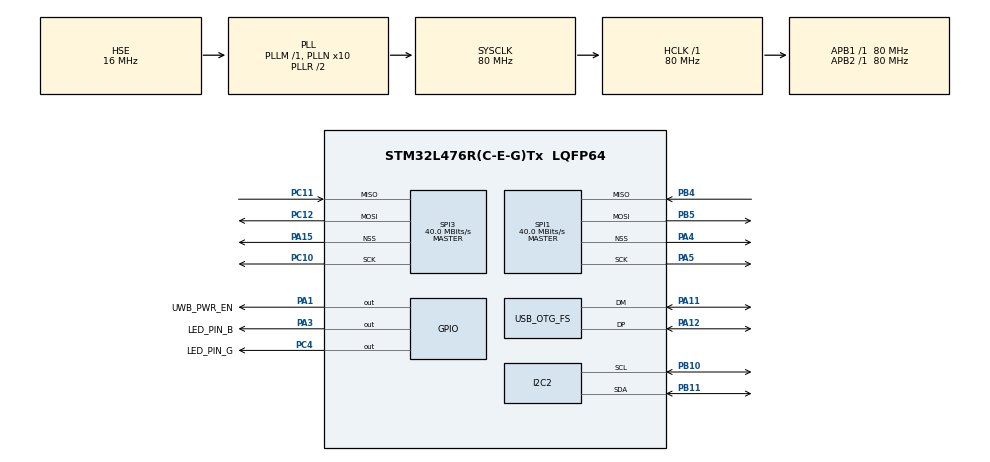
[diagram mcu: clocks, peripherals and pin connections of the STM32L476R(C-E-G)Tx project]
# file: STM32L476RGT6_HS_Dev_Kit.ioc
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I2C2.Timing=0x10D19CE4
Mcu.Family=STM32L4
Mcu.Name=STM32L476R(C-E-G)Tx
Mcu.Package=LQFP64
NVIC.OTG_FS_IRQn=true\:0\:0\:false\:false\:true\:false\:true\:true
NVIC.PriorityGroup=NVIC_PRIORITYGROUP_4
PA1.GPIO_Label=UWB_PWR_EN
PA1.Signal=GPIO_Output
PA11.Mode=Device_Only
PA11.Signal=USB_OTG_FS_DM
PA12.Mode=Device_Only
PA12.Signal=USB_OTG_FS_DP
PA13\ (JTMS-SWDIO).Mode=Trace_Asynchronous_SW
PA13\ (JTMS-SWDIO).Signal=SYS_JTMS-SWDIO
PA14\ (JTCK-SWCLK).Mode=Trace_Asynchronous_SW
PA14\ (JTCK-SWCLK).Signal=SYS_JTCK-SWCLK
PA15\ (JTDI).Mode=NSS_Signal_Hard_Output
PA15\ (JTDI).Signal=SPI3_NSS
PA3.GPIO_Label=LED_PIN_B
PA3.Signal=GPIO_Output
PA4.Mode=NSS_Signal_Hard_Output
PA4.Signal=SPI1_NSS
PA5.Mode=Full_Duplex_Master
PA5.Signal=SPI1_SCK
PB10.Mode=I2C
PB10.Signal=I2C2_SCL
PB11.Mode=I2C
PB11.Signal=I2C2_SDA
PB3\ (JTDO-TRACESWO).Mode=Trace_Asynchronous_SW
PB3\ (JTDO-TRACESWO).Signal=SYS_JTDO-SWO
PB4\ (NJTRST).Mode=Full_Duplex_Master
PB4\ (NJTRST).Signal=SPI1_MISO
PB5.Mode=Full_Duplex_Master
PB5.Signal=SPI1_MOSI
PC10.Mode=Full_Duplex_Master
PC10.Signal=SPI3_SCK
PC11.Mode=Full_Duplex_Master
PC11.Signal=SPI3_MISO
PC12.Mode=Full_Duplex_Master
PC12.Signal=SPI3_MOSI
PC14-OSC32_IN\ (PC14).Mode=LSE-External-Oscillator
PC14-OSC32_IN\ (PC14).Signal=RCC_OSC32_IN
PC15-OSC32_OUT\ (PC15).Mode=LSE-External-Oscillator
PC15-OSC32_OUT\ (PC15).Signal=RCC_OSC32_OUT
PC4.GPIO_Label=LED_PIN_G
PC4.Signal=GPIO_Output
PH0-OSC_IN\ (PH0).Mode=HSE-External-Oscillator
PH0-OSC_IN\ (PH0).Signal=RCC_OSC_IN
PH1-OSC_OUT\ (PH1).Mode=HSE-External-Oscillator
PH1-OSC_OUT\ (PH1).Signal=RCC_OSC_OUT
ProjectManager.HeapSize=0x200
ProjectManager.StackSize=0x400
ProjectManager.TargetToolchain=STM32CubeIDE
RCC.ADCFreq_Value=96000000
RCC.AHBFreq_Value=80000000
RCC.APB1Freq_Value=80000000
RCC.APB1TimFreq_Value=80000000
RCC.APB2Freq_Value=80000000
RCC.APB2TimFreq_Value=80000000
RCC.CortexFreq_Value=80000000
RCC.HCLKFreq_Value=80000000
RCC.HSE_VALUE=16000000
RCC.HSI_VALUE=16000000
RCC.MSI_VALUE=4000000
RCC.PLLN=10
RCC.PLLSAI1N=12
RCC.PLLSAI1Q=RCC_PLLQ_DIV4
RCC.PLLSourceVirtual=RCC_PLLSOURCE_HSE
RCC.RTCClockSelection=RCC_RTCCLKSOURCE_LSE
RCC.SYSCLKFreq_VALUE=80000000
RCC.SYSCLKSource=RCC_SYSCLKSOURCE_PLLCLK
RCC.USBFreq_Value=48000000
RCC.VCOOutputFreq_Value=160000000
SPI1.BaudRatePrescaler=SPI_BAUDRATEPRESCALER_2
SPI1.CalculateBaudRate=40.0 MBits/s
SPI1.Direction=SPI_DIRECTION_2LINES
SPI1.Mode=SPI_MODE_MASTER
SPI1.VirtualNSS=VM_NSSHARD
SPI1.VirtualType=VM_MASTER
SPI3.BaudRatePrescaler=SPI_BAUDRATEPRESCALER_2
SPI3.CalculateBaudRate=40.0 MBits/s
SPI3.Direction=SPI_DIRECTION_2LINES
SPI3.Mode=SPI_MODE_MASTER
SPI3.VirtualNSS=VM_NSSHARD
SPI3.VirtualType=VM_MASTER
USB_DEVICE.CLASS_NAME_FS=CDC
USB_DEVICE.VirtualMode=Cdc
USB_DEVICE.VirtualModeFS=Cdc_FS
USB_OTG_FS.VirtualMode=Device_Only
VP_RTC_VS_RTC_Activate.Mode=RTC_Enabled
VP_USB_DEVICE_VS_USB_DEVICE_CDC_FS.Mode=CDC_FS
board=custom

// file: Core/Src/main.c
/* USER CODE BEGIN Header */
/**
  ******************************************************************************
  * @file           : main.c
  * @brief          : Main program body
  ******************************************************************************
  * @attention
  *
  * Copyright (c) 2025 STMicroelectronics.
  * All rights reserved.
  *
  * This software is licensed under terms that can be found in the LICENSE file
  * in the root directory of this software component.
  * If no LICENSE file comes with this software, it is provided AS-IS.
  *
  ******************************************************************************
  */
/* USER CODE END Header */
#include "main.h"
#include "i2c.h"
#include "rtc.h"
#include "spi.h"
#include "usb_device.h"
#include "gpio.h"
#include "usbd_cdc_if.h"

#include "HS_system.h"

void SystemClock_Config(void);

/* USER CODE BEGIN 0 */
uint8_t TxBuffer[] = "Hello from STM32 USB CDC\r\n";

/* USER CODE END 0 */

int main(void)
{

  /* MCU Configuration--------------------------------------------------------*/

  /* Reset of all peripherals, Initializes the Flash interface and the Systick. */
  HAL_Init();

  /* Configure the system clock */
  SystemClock_Config();

  /* Initialize all configured peripherals */
  MX_GPIO_Init();
  MX_I2C2_Init();
  MX_RTC_Init();
  MX_SPI1_Init();
  MX_SPI3_Init();
  MX_USB_DEVICE_Init();

  /* Infinite loop */
  while (1)
  {
    HAL_GPIO_WritePin(GPIOA, LED_PIN_B_Pin, GPIO_PIN_SET);
    HAL_Delay(50);
    HAL_GPIO_WritePin(GPIOA, LED_PIN_B_Pin, GPIO_PIN_RESET);

    CDC_Transmit_FS(TxBuffer, (uint16_t)sizeof(TxBuffer));

    HAL_GPIO_WritePin(GPIOC, LED_PIN_G_Pin, GPIO_PIN_SET);
    HAL_Delay(50);
    HAL_GPIO_WritePin(GPIOC, LED_PIN_G_Pin, GPIO_PIN_RESET);

    HAL_Delay(900);

  }
}

void SystemClock_Config(void)
{
  RCC_OscInitTypeDef RCC_OscInitStruct = {0};
  RCC_ClkInitTypeDef RCC_ClkInitStruct = {0};

  /** Configure the main internal regulator output voltage
  */
  if (HAL_PWREx_ControlVoltageScaling(PWR_REGULATOR_VOLTAGE_SCALE1) != HAL_OK)
  {
    Error_Handler();
  }

  /** Configure LSE Drive Capability
  */
  HAL_PWR_EnableBkUpAccess();
  __HAL_RCC_LSEDRIVE_CONFIG(RCC_LSEDRIVE_LOW);

  /** Initializes the RCC Oscillators according to the specified parameters
  * in the RCC_OscInitTypeDef structure.
  */
  RCC_OscInitStruct.OscillatorType = RCC_OSCILLATORTYPE_HSE|RCC_OSCILLATORTYPE_LSE;
  RCC_OscInitStruct.HSEState = RCC_HSE_ON;
  RCC_OscInitStruct.LSEState = RCC_LSE_ON;
  RCC_OscInitStruct.PLL.PLLState = RCC_PLL_ON;
  RCC_OscInitStruct.PLL.PLLSource = RCC_PLLSOURCE_HSE;
  RCC_OscInitStruct.PLL.PLLM = 1;
  RCC_OscInitStruct.PLL.PLLN = 10;
  RCC_OscInitStruct.PLL.PLLP = RCC_PLLP_DIV7;
  RCC_OscInitStruct.PLL.PLLQ = RCC_PLLQ_DIV2;
  RCC_OscInitStruct.PLL.PLLR = RCC_PLLR_DIV2;
  if (HAL_RCC_OscConfig(&RCC_OscInitStruct) != HAL_OK)
  {
    Error_Handler();
  }

  /** Initializes the CPU, AHB and APB buses clocks
  */
  RCC_ClkInitStruct.ClockType = RCC_CLOCKTYPE_HCLK|RCC_CLOCKTYPE_SYSCLK
                              |RCC_CLOCKTYPE_PCLK1|RCC_CLOCKTYPE_PCLK2;
  RCC_ClkInitStruct.SYSCLKSource = RCC_SYSCLKSOURCE_PLLCLK;
  RCC_ClkInitStruct.AHBCLKDivider = RCC_SYSCLK_DIV1;
  RCC_ClkInitStruct.APB1CLKDivider = RCC_HCLK_DIV1;
  RCC_ClkInitStruct.APB2CLKDivider = RCC_HCLK_DIV1;

  if (HAL_RCC_ClockConfig(&RCC_ClkInitStruct, FLASH_LATENCY_4) != HAL_OK)
  {
    Error_Handler();
  }
}

void Error_Handler(void)
{
  __disable_irq();
  while (1)
  {
  }
}
